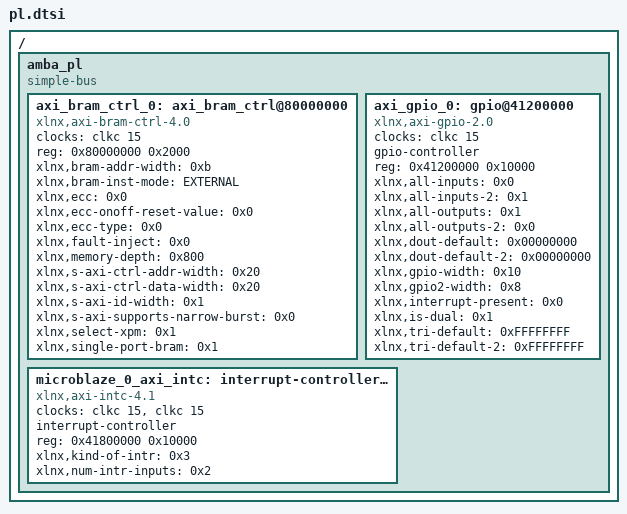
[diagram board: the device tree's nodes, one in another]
/*
 * CAUTION: This file is automatically generated by Xilinx.
 * Version:  
 * Today is: Sat Feb 16 21:35:43 2019
 */


/ {
	amba_pl: amba_pl {
		#address-cells = <1>;
		#size-cells = <1>;
		compatible = "simple-bus";
		ranges ;
		axi_bram_ctrl_0: axi_bram_ctrl@80000000 {
			clock-names = "s_axi_aclk";
			clocks = <&clkc 15>;
			compatible = "xlnx,axi-bram-ctrl-4.0";
			reg = <0x80000000 0x2000>;
			xlnx,bram-addr-width = <0xb>;
			xlnx,bram-inst-mode = "EXTERNAL";
			xlnx,ecc = <0x0>;
			xlnx,ecc-onoff-reset-value = <0x0>;
			xlnx,ecc-type = <0x0>;
			xlnx,fault-inject = <0x0>;
			xlnx,memory-depth = <0x800>;
			xlnx,s-axi-ctrl-addr-width = <0x20>;
			xlnx,s-axi-ctrl-data-width = <0x20>;
			xlnx,s-axi-id-width = <0x1>;
			xlnx,s-axi-supports-narrow-burst = <0x0>;
			xlnx,select-xpm = <0x1>;
			xlnx,single-port-bram = <0x1>;
		};
		axi_gpio_0: gpio@41200000 {
			#gpio-cells = <3>;
			clock-names = "s_axi_aclk";
			clocks = <&clkc 15>;
			compatible = "xlnx,axi-gpio-2.0", "xlnx,xps-gpio-1.00.a";
			gpio-controller ;
			reg = <0x41200000 0x10000>;
			xlnx,all-inputs = <0x0>;
			xlnx,all-inputs-2 = <0x1>;
			xlnx,all-outputs = <0x1>;
			xlnx,all-outputs-2 = <0x0>;
			xlnx,dout-default = <0x00000000>;
			xlnx,dout-default-2 = <0x00000000>;
			xlnx,gpio-width = <0x10>;
			xlnx,gpio2-width = <0x8>;
			xlnx,interrupt-present = <0x0>;
			xlnx,is-dual = <0x1>;
			xlnx,tri-default = <0xFFFFFFFF>;
			xlnx,tri-default-2 = <0xFFFFFFFF>;
		};
		microblaze_0_axi_intc: interrupt-controller@41800000 {
			#interrupt-cells = <2>;
			clock-names = "s_axi_aclk", "processor_clk";
			clocks = <&clkc 15>, <&clkc 15>;
			compatible = "xlnx,axi-intc-4.1", "xlnx,xps-intc-1.00.a";
			interrupt-controller ;
			reg = <0x41800000 0x10000>;
			xlnx,kind-of-intr = <0x3>;
			xlnx,num-intr-inputs = <0x2>;
		};
	};
};
